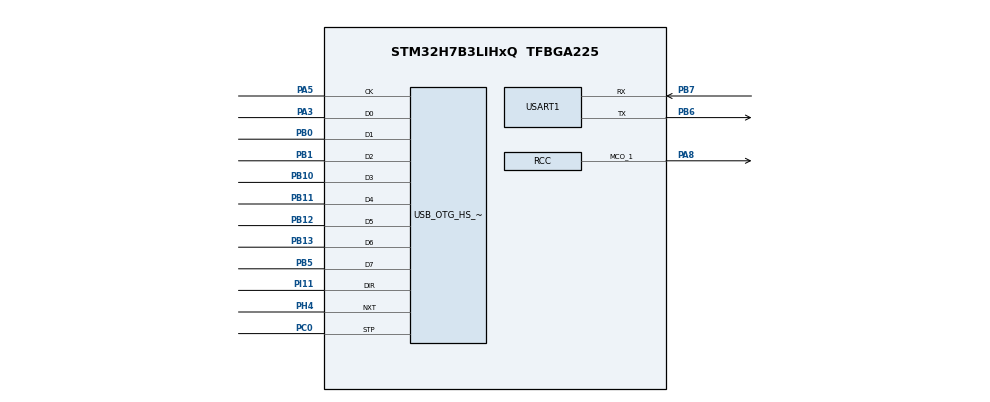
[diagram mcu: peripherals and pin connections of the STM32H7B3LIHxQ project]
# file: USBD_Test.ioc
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AL94.I-CUBE-USBD-COMPOSITE.1.0.3.CompositeCcUSBJjCOMPOSITEJjCDCIiACM=true
AL94.I-CUBE-USBD-COMPOSITE.1.0.3.CompositeCcUSBJjCOMPOSITEJjCDCIiECM=true
AL94.I-CUBE-USBD-COMPOSITE.1.0.3.CompositeCcUSBJjCOMPOSITEJjCDCIiRNDIS=true
AL94.I-CUBE-USBD-COMPOSITE.1.0.3.CompositeCcUSBJjCOMPOSITEJjCOMPOSITE=true
AL94.I-CUBE-USBD-COMPOSITE.1.0.3.CompositeCcUSBJjCOMPOSITEJjCore=true
AL94.I-CUBE-USBD-COMPOSITE.1.0.3.CompositeCcUSBJjCOMPOSITEJjDFU=true
AL94.I-CUBE-USBD-COMPOSITE.1.0.3.CompositeCcUSBJjCOMPOSITEJjHIDIiCUSTOM=true
AL94.I-CUBE-USBD-COMPOSITE.1.0.3.CompositeCcUSBJjCOMPOSITEJjHIDIiKEYBOARD=true
AL94.I-CUBE-USBD-COMPOSITE.1.0.3.CompositeCcUSBJjCOMPOSITEJjHIDIiMOUSE=true
AL94.I-CUBE-USBD-COMPOSITE.1.0.3.CompositeCcUSBJjCOMPOSITEJjMSCIiBOT=true
AL94.I-CUBE-USBD-COMPOSITE.1.0.3.CompositeCcUSBJjCOMPOSITEJjPRINTER=true
AL94.I-CUBE-USBD-COMPOSITE.1.0.3.CompositeCcUSBJjCOMPOSITEJjUACIiMIC=true
AL94.I-CUBE-USBD-COMPOSITE.1.0.3.CompositeCcUSBJjCOMPOSITEJjUACIiSPKR=true
AL94.I-CUBE-USBD-COMPOSITE.1.0.3.CompositeCcUSBJjCOMPOSITEJjUVC=true
AL94.I-CUBE-USBD-COMPOSITE.1.0.3._USBD_USE_CDC_ACM=true
AL94.I-CUBE-USBD-COMPOSITE.1.0.3._USBD_USE_CDC_ECM=true
AL94.I-CUBE-USBD-COMPOSITE.1.0.3._USBD_USE_CDC_RNDIS=true
AL94.I-CUBE-USBD-COMPOSITE.1.0.3._USBD_USE_DFU=true
AL94.I-CUBE-USBD-COMPOSITE.1.0.3._USBD_USE_HID_CUSTOM=true
AL94.I-CUBE-USBD-COMPOSITE.1.0.3._USBD_USE_HID_KEYBOARD=true
AL94.I-CUBE-USBD-COMPOSITE.1.0.3._USBD_USE_HID_MOUSE=true
AL94.I-CUBE-USBD-COMPOSITE.1.0.3._USBD_USE_HS=true
AL94.I-CUBE-USBD-COMPOSITE.1.0.3._USBD_USE_MSC=true
AL94.I-CUBE-USBD-COMPOSITE.1.0.3._USBD_USE_PRNTR=true
AL94.I-CUBE-USBD-COMPOSITE.1.0.3._USBD_USE_UAC_MIC=true
AL94.I-CUBE-USBD-COMPOSITE.1.0.3._USBD_USE_UAC_SPKR=true
AL94.I-CUBE-USBD-COMPOSITE.1.0.3._USBD_USE_UVC=true
Mcu.Family=STM32H7
Mcu.Name=STM32H7B3LIHxQ
Mcu.Package=TFBGA225
NVIC.OTG_HS_IRQn=true\:0\:0\:false\:false\:true\:true\:true
NVIC.PriorityGroup=NVIC_PRIORITYGROUP_4
PA3.Mode=Device_HS
PA3.Signal=USB_OTG_HS_ULPI_D0
PA5.Mode=Device_HS
PA5.Signal=USB_OTG_HS_ULPI_CK
PA8.Mode=Clock-out-1
PA8.Signal=RCC_MCO_1
PB0.Mode=Device_HS
PB0.Signal=USB_OTG_HS_ULPI_D1
PB1.Mode=Device_HS
PB1.Signal=USB_OTG_HS_ULPI_D2
PB10.Mode=Device_HS
PB10.Signal=USB_OTG_HS_ULPI_D3
PB11.Mode=Device_HS
PB11.Signal=USB_OTG_HS_ULPI_D4
PB12.Mode=Device_HS
PB12.Signal=USB_OTG_HS_ULPI_D5
PB13.Mode=Device_HS
PB13.Signal=USB_OTG_HS_ULPI_D6
PB5.Mode=Device_HS
PB5.Signal=USB_OTG_HS_ULPI_D7
PB6.Mode=Asynchronous
PB6.Signal=USART1_TX
PB7.Mode=Asynchronous
PB7.Signal=USART1_RX
PC0.Mode=Device_HS
PC0.Signal=USB_OTG_HS_ULPI_STP
PH0-OSC_IN.Mode=HSE-External-Oscillator
PH0-OSC_IN.Signal=RCC_OSC_IN
PH1-OSC_OUT.Mode=HSE-External-Oscillator
PH1-OSC_OUT.Signal=RCC_OSC_OUT
PH4.Mode=Device_HS
PH4.Signal=USB_OTG_HS_ULPI_NXT
PI11.Mode=Device_HS
PI11.Signal=USB_OTG_HS_ULPI_DIR
ProjectManager.HeapSize=0x200
ProjectManager.StackSize=0x400
ProjectManager.TargetToolchain=STM32CubeIDE
RCC.ADCFreq_Value=200000000
RCC.APB1Freq_Value=72000000
RCC.APB2Freq_Value=72000000
RCC.APB3Freq_Value=72000000
RCC.APB4Freq_Value=72000000
RCC.CortexFreq_Value=72000000
RCC.DIVM1=2
RCC.DIVM2=12
RCC.DIVM3=24
RCC.DIVN1=12
RCC.DIVN2=200
RCC.DIVN3=192
RCC.DIVP3=17
RCC.DIVQ1=3
RCC.DIVR1=4
RCC.DIVR2=4
RCC.FMCCLockSelection=RCC_FMCCLKSOURCE_PLL2
RCC.HCLKFreq_Value=72000000
RCC.PLL2FRACN=0
RCC.PLL3FRACN=0
RCC.PLLFRACN=0
RCC.PLLSourceVirtual=RCC_PLLSOURCE_HSE
RCC.PWR_Regulator_Voltage_Scale=PWR_REGULATOR_VOLTAGE_SCALE0
RCC.QSPICLockSelection=RCC_OSPICLKSOURCE_PLL2
RCC.RCC_MCO1Source=RCC_MCO1SOURCE_HSE
RCC.RTCClockSelection=RCC_RTCCLKSOURCE_LSE
RCC.SDMMC1CLockSelection=RCC_SDMMCCLKSOURCE_PLL2
RCC.SPI123CLockSelection=RCC_SPI123CLKSOURCE_CLKP
RCC.SYSCLKFreq_VALUE=72000000
RCC.SYSCLKSource=RCC_SYSCLKSOURCE_PLLCLK
RCC.SupplySource=PWR_DIRECT_SMPS_SUPPLY
RCC.USBFreq_Value=48000000
USART1.VirtualMode-Asynchronous=VM_ASYNC
USB_OTG_HS.VirtualMode-Device_HS=Device_HS
VP_AL94.I-CUBE-USBD-COMPOSITE_VS_USBJjComposite_1.0.0_1.0.3.Mode=USBJjComposite
board=STM32H7B3I-DK

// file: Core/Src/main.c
/* USER CODE BEGIN Header */
/**
  ******************************************************************************
  * @file           : main.c
  * @brief          : Main program body
  ******************************************************************************
  * @attention
  *
  * <h2><center>&copy; Copyright (c) 2021 STMicroelectronics.
  * All rights reserved.</center></h2>
  *
  * This software component is licensed by ST under BSD 3-Clause license,
  * the "License"; You may not use this file except in compliance with the
  * License. You may obtain a copy of the License at:
  *                        opensource.org/licenses/BSD-3-Clause
  *
  ******************************************************************************
  */
/* USER CODE END Header */
#include "main.h"
#include "usart.h"
#include "usb_otg.h"
#include "gpio.h"

/* USER CODE BEGIN Includes */
#include "usb_device.h"
/* USER CODE END Includes */

void SystemClock_Config(void);

int main(void)
{

  /* MCU Configuration--------------------------------------------------------*/

  /* Reset of all peripherals, Initializes the Flash interface and the Systick. */
  HAL_Init();

  /* Configure the system clock */
  SystemClock_Config();

  /* Initialize all configured peripherals */
  MX_GPIO_Init();
  MX_USB_OTG_HS_PCD_Init();
  MX_USART1_UART_Init();
  /* USER CODE BEGIN 2 */
  MX_USB_DEVICE_Init();
  /* USER CODE END 2 */

  /* Infinite loop */
  while (1)
  {

  }
}

void SystemClock_Config(void)
{
  RCC_OscInitTypeDef RCC_OscInitStruct = {0};
  RCC_ClkInitTypeDef RCC_ClkInitStruct = {0};

  /** Supply configuration update enable
  */
  HAL_PWREx_ConfigSupply(PWR_DIRECT_SMPS_SUPPLY);
  /** Configure the main internal regulator output voltage
  */
  __HAL_PWR_VOLTAGESCALING_CONFIG(PWR_REGULATOR_VOLTAGE_SCALE0);

  while(!__HAL_PWR_GET_FLAG(PWR_FLAG_VOSRDY)) {}
  /** Initializes the RCC Oscillators according to the specified parameters
  * in the RCC_OscInitTypeDef structure.
  */
  RCC_OscInitStruct.OscillatorType = RCC_OSCILLATORTYPE_HSE;
  RCC_OscInitStruct.HSEState = RCC_HSE_ON;
  RCC_OscInitStruct.PLL.PLLState = RCC_PLL_ON;
  RCC_OscInitStruct.PLL.PLLSource = RCC_PLLSOURCE_HSE;
  RCC_OscInitStruct.PLL.PLLM = 2;
  RCC_OscInitStruct.PLL.PLLN = 12;
  RCC_OscInitStruct.PLL.PLLP = 2;
  RCC_OscInitStruct.PLL.PLLQ = 3;
  RCC_OscInitStruct.PLL.PLLR = 4;
  RCC_OscInitStruct.PLL.PLLRGE = RCC_PLL1VCIRANGE_3;
  RCC_OscInitStruct.PLL.PLLVCOSEL = RCC_PLL1VCOWIDE;
  RCC_OscInitStruct.PLL.PLLFRACN = 0;
  if (HAL_RCC_OscConfig(&RCC_OscInitStruct) != HAL_OK)
  {
    Error_Handler();
  }
  /** Initializes the CPU, AHB and APB buses clocks
  */
  RCC_ClkInitStruct.ClockType = RCC_CLOCKTYPE_HCLK|RCC_CLOCKTYPE_SYSCLK
                              |RCC_CLOCKTYPE_PCLK1|RCC_CLOCKTYPE_PCLK2
                              |RCC_CLOCKTYPE_D3PCLK1|RCC_CLOCKTYPE_D1PCLK1;
  RCC_ClkInitStruct.SYSCLKSource = RCC_SYSCLKSOURCE_PLLCLK;
  RCC_ClkInitStruct.SYSCLKDivider = RCC_SYSCLK_DIV1;
  RCC_ClkInitStruct.AHBCLKDivider = RCC_HCLK_DIV1;
  RCC_ClkInitStruct.APB3CLKDivider = RCC_APB3_DIV1;
  RCC_ClkInitStruct.APB1CLKDivider = RCC_APB1_DIV1;
  RCC_ClkInitStruct.APB2CLKDivider = RCC_APB2_DIV1;
  RCC_ClkInitStruct.APB4CLKDivider = RCC_APB4_DIV1;

  if (HAL_RCC_ClockConfig(&RCC_ClkInitStruct, FLASH_LATENCY_1) != HAL_OK)
  {
    Error_Handler();
  }
  HAL_RCC_MCOConfig(RCC_MCO1, RCC_MCO1SOURCE_HSE, RCC_MCODIV_1);
}

void Error_Handler(void)
{
  __disable_irq();
  while (1)
  {
  }
}
